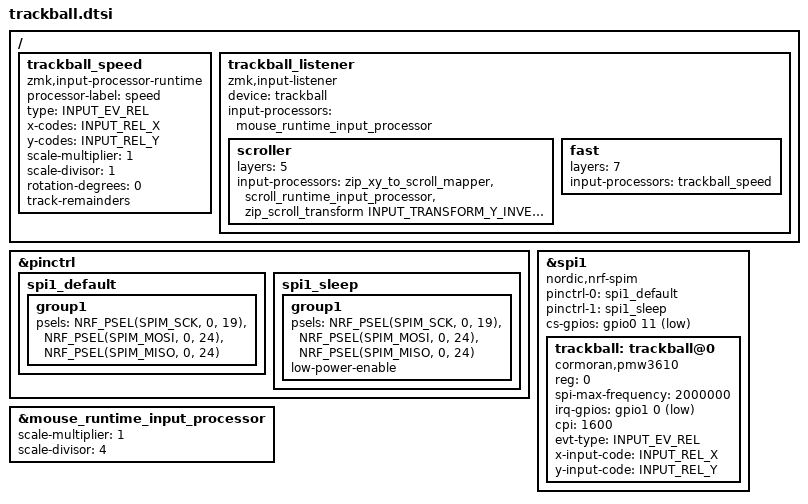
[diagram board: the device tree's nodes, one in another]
#include <zephyr/dt-bindings/input/input-event-codes.h>
#include <dt-bindings/zmk/input_transform.h>
#include <input/processors.dtsi>
#include <input/processors/runtime-input-processor.dtsi>

&pinctrl {
    spi1_default: spi1_default {
        group1 {
            psels = <NRF_PSEL(SPIM_SCK, 0, 19)>,
                <NRF_PSEL(SPIM_MOSI, 0, 24)>,
                <NRF_PSEL(SPIM_MISO, 0, 24)>;
        };
    };

    spi1_sleep: spi1_sleep {
        group1 {
            psels = <NRF_PSEL(SPIM_SCK, 0, 19)>,
                <NRF_PSEL(SPIM_MOSI, 0, 24)>,
                <NRF_PSEL(SPIM_MISO, 0, 24)>;
            low-power-enable;
        };
    };
};

&spi1 {
    status = "okay";
    compatible = "nordic,nrf-spim";
    pinctrl-0 = <&spi1_default>;
    pinctrl-1 = <&spi1_sleep>;
    pinctrl-names = "default", "sleep";
    cs-gpios = <&gpio0 11 GPIO_ACTIVE_LOW>;

    trackball: trackball@0 {
        status = "okay";
        compatible = "cormoran,pmw3610";
        reg = <0>;
        spi-max-frequency = <2000000>;
        irq-gpios = <&gpio1 0 (GPIO_ACTIVE_LOW | GPIO_PULL_UP)>;
        cpi = <1600>;
        evt-type = <INPUT_EV_REL>;
        x-input-code = <INPUT_REL_X>;
        y-input-code = <INPUT_REL_Y>;
    };
};

/*
 * 轨迹球的输入处理器链，完全由「当前激活层」决定，不使用任何 behavior。
 *
 *   基准链（层 0，或未命中下面任何层） →  mouse（scale = 1/4，日常慢速）
 *   层 5                              →  xy_to_scroll + scroll runtime processor
 *   层 7                              →  speed（scale = 1/1，全速）
 *
 * 语义（ZMK input_listener 的 layer_overrides）：子节点按书写顺序匹配，
 * 第一个命中的层会让它的 input-processors **整体替换**父级链
 * （没写 process-next）；所有子节点都没命中时才走父级链。
 *
 * 两条鼠标链互不共享处理器，各自独立：
 *   - mouse 只服务基准层 → 改它不影响层 7
 *   - speed 只服务层 7   → 改它不影响基准层
 * 所以速度是「各自的绝对值」，不再相乘：
 *   基准 = CPI × 1/4，层 7 = CPI × 1/1。
 *
 * 进层 7 的方式：config/velvet.keymap 里左拇指空格是 &ltq 7 SPACE
 * （按住 = &mo 7，轻按 = 空格）。
 *
 * ⚠ DT 里写的只是**默认值**，NVS 里已存在的值优先级更高。首次刷入后若
 * 表现与预期相反（默认快、按住反而慢），到 DYA Studio → 输入处理器 把
 * mouse 改成 1/4、speed 改成 1/1 即可，不需要重新编译。
 *
 * 方向校准不要用 runtime processor 的 rotation：它在 rotation != 0 时要求
 * X/Y 严格成对到达，单轴输入会被吞成 0（input_processor_runtime.c 里的
 * `event->value = 0` 分支），表现为丢轴、方向错乱。请用驱动层
 * CONFIG_PMW3610_SWAP_XY / _INVERT_X / _INVERT_Y。
 */
/ {
    /* 层 7 专用：全速（1/1）。与 mouse 完全独立，互不影响 */
    trackball_speed: trackball_speed {
        compatible = "zmk,input-processor-runtime";
        processor-label = "speed";
        type = <INPUT_EV_REL>;
        x-codes = <INPUT_REL_X>;
        y-codes = <INPUT_REL_Y>;
        scale-multiplier = <1>;
        scale-divisor = <1>;
        rotation-degrees = <0>;
        track-remainders;
        #input-processor-cells = <0>;
    };

    trackball_listener {
        status = "okay";
        compatible = "zmk,input-listener";
        device = <&trackball>;

        /* 基准链：慢速日常，mouse 的 scale 见文件末尾的默认值覆盖 */
        input-processors = <&mouse_runtime_input_processor>;

        /* 层 5：轨迹球转滚动（保持原有行为） */
        scroller {
            layers = <5>;
            input-processors =
                <&zip_xy_to_scroll_mapper &scroll_runtime_input_processor>,
                <&zip_scroll_transform INPUT_TRANSFORM_Y_INVERT>;
        };

        /* 层 7：全速。链里没有 mouse，两条链彻底解耦 */
        fast {
            layers = <7>;
            input-processors = <&trackball_speed>;
        };
    };
};

/*
 * 把模块预定义的 mouse 处理器默认 scale 改成 1/4（慢速基准）。
 * 它自带 track-remainders，缩小时小位移会累积，不会出现「推了不动」。
 * 仍然受 NVS 覆盖：Studio 里改过的值优先，改这段只影响 NVS 为空时。
 */
&mouse_runtime_input_processor {
    scale-multiplier = <1>;
    scale-divisor = <4>;
};
